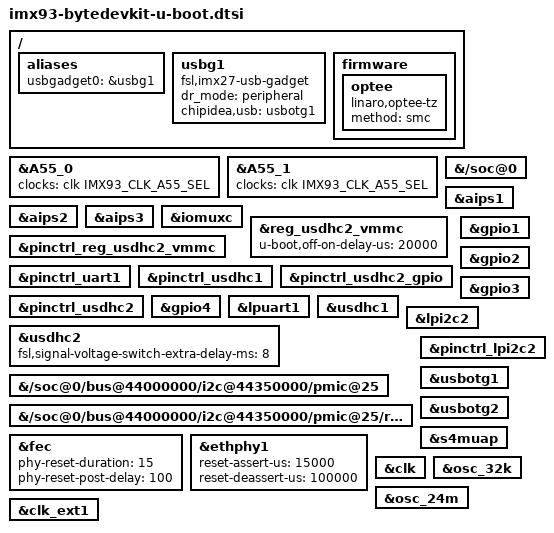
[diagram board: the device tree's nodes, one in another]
// SPDX-License-Identifier: GPL-2.0+
/*
 * Copyright (C) 2026 bytesatwork AG - https://www.bytesatwork.io
 *
 * Based on imx93-11x11-evk-u-boot.dtsi
 * Copyright 2022 NXP
 */

#include "imx93-u-boot.dtsi"

/ {
	aliases {
		usbgadget0 = &usbg1;
	};

	usbg1: usbg1 {
		compatible = "fsl,imx27-usb-gadget";
		dr_mode = "peripheral";
		chipidea,usb = <&usbotg1>;
		status = "okay";
	};

	firmware {
		optee {
			compatible = "linaro,optee-tz";
			method = "smc";
		};
	};
};

&A55_0 {
	clocks = <&clk IMX93_CLK_A55_SEL>;
};

&A55_1 {
	clocks = <&clk IMX93_CLK_A55_SEL>;
};

&{/soc@0} {
	bootph-all;
	bootph-pre-ram;
};

&aips1 {
	bootph-pre-ram;
	bootph-all;
};

&aips2 {
	bootph-pre-ram;
	bootph-some-ram;
};

&aips3 {
	bootph-pre-ram;
	bootph-some-ram;
};

&iomuxc {
	bootph-pre-ram;
	bootph-some-ram;
};

&reg_usdhc2_vmmc {
	u-boot,off-on-delay-us = <20000>;
	bootph-pre-ram;
};

&pinctrl_reg_usdhc2_vmmc {
	bootph-pre-ram;
};

&pinctrl_uart1 {
	bootph-pre-ram;
	bootph-some-ram;
};

&pinctrl_usdhc1 {
	bootph-pre-ram;
};

&pinctrl_usdhc2_gpio {
	bootph-pre-ram;
};

&pinctrl_usdhc2 {
	bootph-pre-ram;
};

&gpio1 {
	bootph-pre-ram;
	bootph-some-ram;
};

&gpio2 {
	bootph-pre-ram;
	bootph-some-ram;
};

&gpio3 {
	bootph-pre-ram;
	bootph-some-ram;
};

&gpio4 {
	bootph-pre-ram;
	bootph-some-ram;
};

&lpuart1 {
	bootph-pre-ram;
	bootph-some-ram;
};

&usdhc1 {
	bootph-pre-ram;
};

&usdhc2 {
	bootph-pre-ram;
	fsl,signal-voltage-switch-extra-delay-ms = <8>;
};

&lpi2c2 {
	bootph-pre-ram;
};

&{/soc@0/bus@44000000/i2c@44350000/pmic@25} {
	bootph-pre-ram;
};

&{/soc@0/bus@44000000/i2c@44350000/pmic@25/regulators} {
	bootph-pre-ram;
};

&pinctrl_lpi2c2 {
	bootph-pre-ram;
};

&fec {
	/* phy-reset-gpios is on unsupported GPIO expander */
	phy-reset-duration = <15>;
	phy-reset-post-delay = <100>;
};

&ethphy1 {
	/* reset-gpios is on unsupported GPIO expander */
	reset-assert-us = <15000>;
	reset-deassert-us = <100000>;
};

&usbotg1 {
	status = "okay";
};

&usbotg2 {
	status = "okay";
};

&s4muap {
	bootph-pre-ram;
	bootph-some-ram;
	status = "okay";
};

&clk {
	bootph-all;
	bootph-pre-ram;
	/delete-property/ assigned-clocks;
	/delete-property/ assigned-clock-rates;
	/delete-property/ assigned-clock-parents;
};

&osc_32k {
	bootph-all;
	bootph-pre-ram;
};

&osc_24m {
	bootph-all;
	bootph-pre-ram;
};

&clk_ext1 {
	bootph-all;
	bootph-pre-ram;
};
